# Espressif register map
File version: 1.0
CPU: Xtensa LX6 1, little endian, no MPU, FPU, 3 interrupt priority bits
Registers are 32-bit, access not given, reset 0x0 unless marked. A register's access mark holds for its fields unless they carry their own. Offsets are from the block's base; [hi:lo] are bit positions; {n}, {i} and the like mark numbered series.

## PWM0
Base 0x00000000
Same registers: PWM1 0x3FF6C000, PWM2 0x3FF6F000, PWM3 0x3FF70000
0x00 MCPWM_CLK_CFG
  [7:0] MCPWM_CLK_PRESCALE
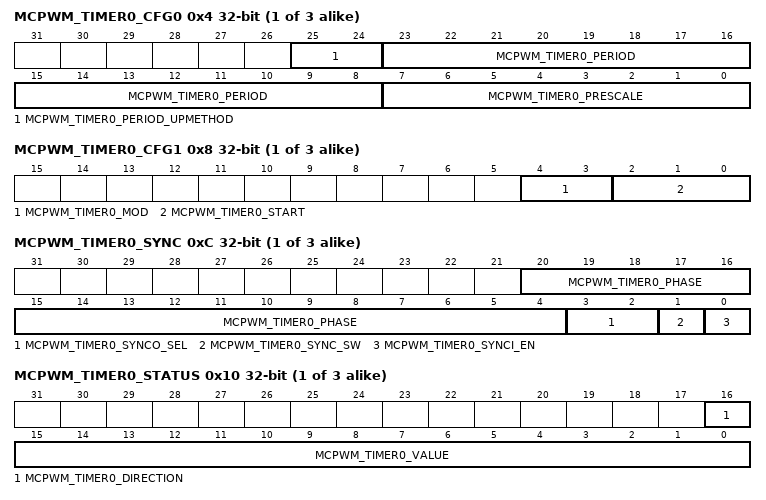
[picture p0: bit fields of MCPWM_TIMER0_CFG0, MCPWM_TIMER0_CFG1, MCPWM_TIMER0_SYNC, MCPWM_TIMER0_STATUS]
{0x4+0x10*i} MCPWM_TIMER{i}_CFG0 (i=0..2)
  [25:24] MCPWM_TIMER{i}_PERIOD_UPMETHOD, [23:8] MCPWM_TIMER{i}_PERIOD, [7:0] MCPWM_TIMER{i}_PRESCALE
{0x8+0x10*i} MCPWM_TIMER{i}_CFG1 (i=0..2)
  [4:3] MCPWM_TIMER{i}_MOD, [2:0] MCPWM_TIMER{i}_START
{0xC+0x10*i} MCPWM_TIMER{i}_SYNC (i=0..2)
  [20:4] MCPWM_TIMER{i}_PHASE, [3:2] MCPWM_TIMER{i}_SYNCO_SEL, [1] MCPWM_TIMER{i}_SYNC_SW, [0] MCPWM_TIMER{i}_SYNCI_EN
{0x10+0x10*i} MCPWM_TIMER{i}_STATUS (i=0..2)
  [16] MCPWM_TIMER{i}_DIRECTION, [15:0] MCPWM_TIMER{i}_VALUE
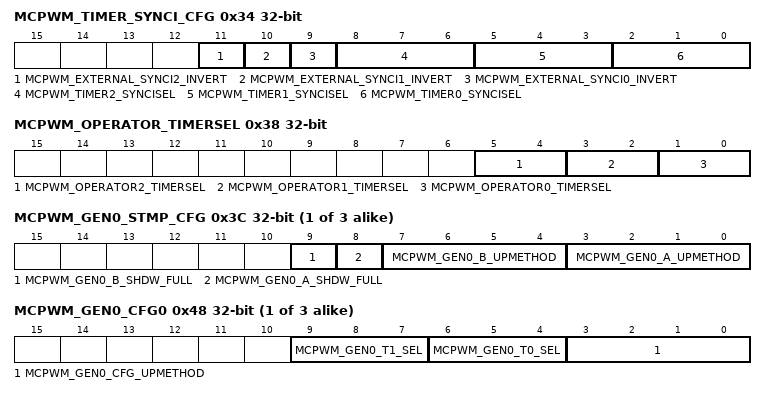
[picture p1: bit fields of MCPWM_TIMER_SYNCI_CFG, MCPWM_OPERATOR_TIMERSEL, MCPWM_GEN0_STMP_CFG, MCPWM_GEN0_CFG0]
0x34 MCPWM_TIMER_SYNCI_CFG
  [11] MCPWM_EXTERNAL_SYNCI2_INVERT, [10] MCPWM_EXTERNAL_SYNCI1_INVERT, [9] MCPWM_EXTERNAL_SYNCI0_INVERT, [8:6] MCPWM_TIMER2_SYNCISEL, [5:3] MCPWM_TIMER1_SYNCISEL, [2:0] MCPWM_TIMER0_SYNCISEL
0x38 MCPWM_OPERATOR_TIMERSEL
  [5:4] MCPWM_OPERATOR2_TIMERSEL, [3:2] MCPWM_OPERATOR1_TIMERSEL, [1:0] MCPWM_OPERATOR0_TIMERSEL
{0x3C+0x38*i} MCPWM_GEN{i}_STMP_CFG (i=0..2)
  [9] MCPWM_GEN{i}_B_SHDW_FULL, [8] MCPWM_GEN{i}_A_SHDW_FULL, [7:4] MCPWM_GEN{i}_B_UPMETHOD, [3:0] MCPWM_GEN{i}_A_UPMETHOD
{0x40+0x38*i} MCPWM_GEN{i}_TSTMP_A (i=0..2)
  [15:0] MCPWM_GEN{i}_A
{0x44+0x38*i} MCPWM_GEN{i}_TSTMP_B (i=0..2)
  [15:0] MCPWM_GEN{i}_B
{0x48+0x38*i} MCPWM_GEN{i}_CFG0 (i=0..2)
  [9:7] MCPWM_GEN{i}_T1_SEL, [6:4] MCPWM_GEN{i}_T0_SEL, [3:0] MCPWM_GEN{i}_CFG_UPMETHOD
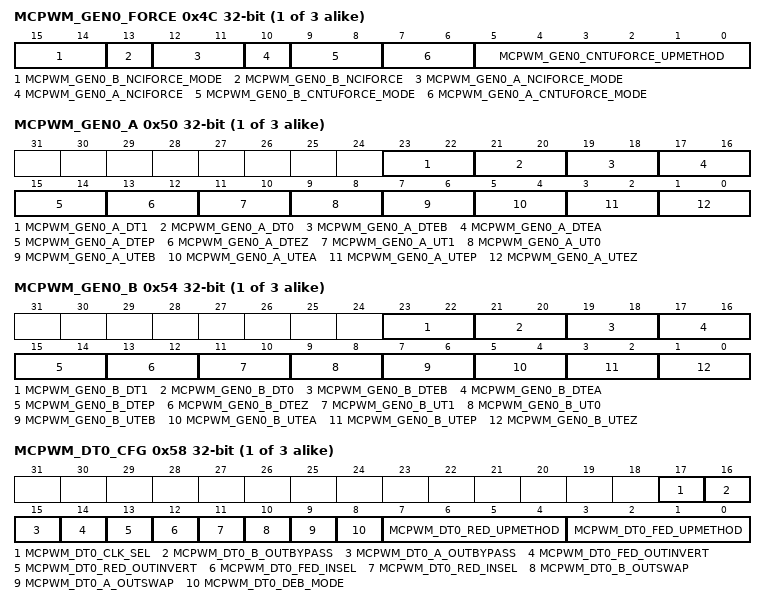
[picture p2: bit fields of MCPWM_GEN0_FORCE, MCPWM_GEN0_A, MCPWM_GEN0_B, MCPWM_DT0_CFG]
{0x4C+0x38*i} MCPWM_GEN{i}_FORCE (i=0..2)
  [15:14] MCPWM_GEN{i}_B_NCIFORCE_MODE, [13] MCPWM_GEN{i}_B_NCIFORCE, [12:11] MCPWM_GEN{i}_A_NCIFORCE_MODE, [10] MCPWM_GEN{i}_A_NCIFORCE, [9:8] MCPWM_GEN{i}_B_CNTUFORCE_MODE, [7:6] MCPWM_GEN{i}_A_CNTUFORCE_MODE, [5:0] MCPWM_GEN{i}_CNTUFORCE_UPMETHOD
{0x50+0x38*i} MCPWM_GEN{i}_A (i=0..2)
  [23:22] MCPWM_GEN{i}_A_DT1, [21:20] MCPWM_GEN{i}_A_DT0, [19:18] MCPWM_GEN{i}_A_DTEB, [17:16] MCPWM_GEN{i}_A_DTEA, [15:14] MCPWM_GEN{i}_A_DTEP, [13:12] MCPWM_GEN{i}_A_DTEZ, [11:10] MCPWM_GEN{i}_A_UT1, [9:8] MCPWM_GEN{i}_A_UT0, [7:6] MCPWM_GEN{i}_A_UTEB, [5:4] MCPWM_GEN{i}_A_UTEA, [3:2] MCPWM_GEN{i}_A_UTEP, [1:0] MCPWM_GEN{i}_A_UTEZ
{0x54+0x38*i} MCPWM_GEN{i}_B (i=0..2)
  [23:22] MCPWM_GEN{i}_B_DT1, [21:20] MCPWM_GEN{i}_B_DT0, [19:18] MCPWM_GEN{i}_B_DTEB, [17:16] MCPWM_GEN{i}_B_DTEA, [15:14] MCPWM_GEN{i}_B_DTEP, [13:12] MCPWM_GEN{i}_B_DTEZ, [11:10] MCPWM_GEN{i}_B_UT1, [9:8] MCPWM_GEN{i}_B_UT0, [7:6] MCPWM_GEN{i}_B_UTEB, [5:4] MCPWM_GEN{i}_B_UTEA, [3:2] MCPWM_GEN{i}_B_UTEP, [1:0] MCPWM_GEN{i}_B_UTEZ
{0x58+0x38*i} MCPWM_DT{i}_CFG (i=0..2)
  [17] MCPWM_DT{i}_CLK_SEL, [16] MCPWM_DT{i}_B_OUTBYPASS, [15] MCPWM_DT{i}_A_OUTBYPASS, [14] MCPWM_DT{i}_FED_OUTINVERT, [13] MCPWM_DT{i}_RED_OUTINVERT, [12] MCPWM_DT{i}_FED_INSEL, [11] MCPWM_DT{i}_RED_INSEL, [10] MCPWM_DT{i}_B_OUTSWAP, [9] MCPWM_DT{i}_A_OUTSWAP, [8] MCPWM_DT{i}_DEB_MODE, [7:4] MCPWM_DT{i}_RED_UPMETHOD, [3:0] MCPWM_DT{i}_FED_UPMETHOD
{0x5C+0x38*i} MCPWM_DT{i}_FED_CFG (i=0..2)
  [15:0] MCPWM_DT{i}_FED
{0x60+0x38*i} MCPWM_DT{i}_RED_CFG (i=0..2)
  [15:0] MCPWM_DT{i}_RED
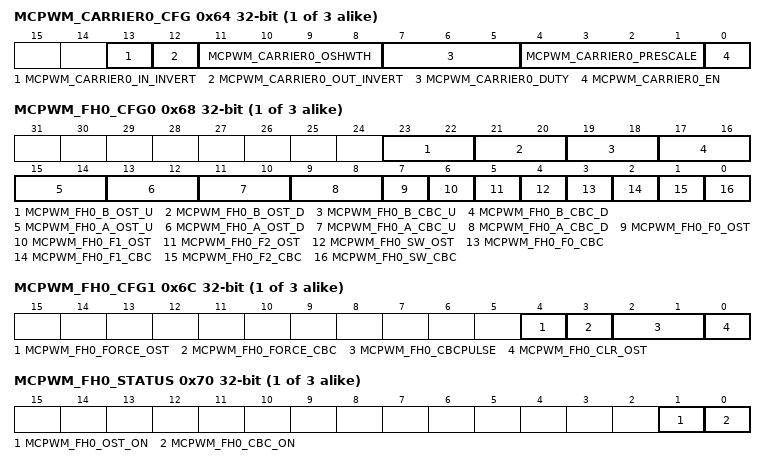
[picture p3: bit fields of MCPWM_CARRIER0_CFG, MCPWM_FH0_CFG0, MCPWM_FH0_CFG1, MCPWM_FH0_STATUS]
{0x64+0x38*i} MCPWM_CARRIER{i}_CFG (i=0..2)
  [13] MCPWM_CARRIER{i}_IN_INVERT, [12] MCPWM_CARRIER{i}_OUT_INVERT, [11:8] MCPWM_CARRIER{i}_OSHWTH, [7:5] MCPWM_CARRIER{i}_DUTY, [4:1] MCPWM_CARRIER{i}_PRESCALE, [0] MCPWM_CARRIER{i}_EN
{0x68+0x38*i} MCPWM_FH{i}_CFG0 (i=0..2)
  [23:22] MCPWM_FH{i}_B_OST_U, [21:20] MCPWM_FH{i}_B_OST_D, [19:18] MCPWM_FH{i}_B_CBC_U, [17:16] MCPWM_FH{i}_B_CBC_D, [15:14] MCPWM_FH{i}_A_OST_U, [13:12] MCPWM_FH{i}_A_OST_D, [11:10] MCPWM_FH{i}_A_CBC_U, [9:8] MCPWM_FH{i}_A_CBC_D, [7] MCPWM_FH{i}_F0_OST, [6] MCPWM_FH{i}_F1_OST, [5] MCPWM_FH{i}_F2_OST, [4] MCPWM_FH{i}_SW_OST, [3] MCPWM_FH{i}_F0_CBC, [2] MCPWM_FH{i}_F1_CBC, [1] MCPWM_FH{i}_F2_CBC, [0] MCPWM_FH{i}_SW_CBC
{0x6C+0x38*i} MCPWM_FH{i}_CFG1 (i=0..2)
  [4] MCPWM_FH{i}_FORCE_OST, [3] MCPWM_FH{i}_FORCE_CBC, [2:1] MCPWM_FH{i}_CBCPULSE, [0] MCPWM_FH{i}_CLR_OST
{0x70+0x38*i} MCPWM_FH{i}_STATUS (i=0..2)
  [1] MCPWM_FH{i}_OST_ON, [0] MCPWM_FH{i}_CBC_ON
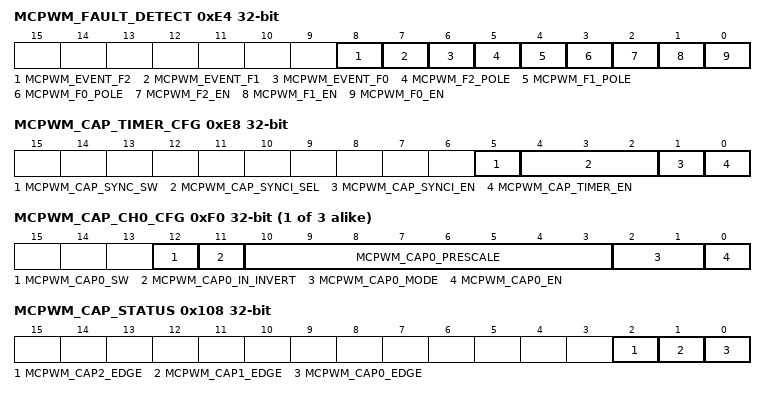
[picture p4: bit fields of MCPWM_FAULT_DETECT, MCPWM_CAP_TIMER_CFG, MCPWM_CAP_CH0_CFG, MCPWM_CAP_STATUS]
0xE4 MCPWM_FAULT_DETECT
  [8] MCPWM_EVENT_F2, [7] MCPWM_EVENT_F1, [6] MCPWM_EVENT_F0, [5] MCPWM_F2_POLE, [4] MCPWM_F1_POLE, [3] MCPWM_F0_POLE, [2] MCPWM_F2_EN, [1] MCPWM_F1_EN, [0] MCPWM_F0_EN
0xE8 MCPWM_CAP_TIMER_CFG
  [5] MCPWM_CAP_SYNC_SW, [4:2] MCPWM_CAP_SYNCI_SEL, [1] MCPWM_CAP_SYNCI_EN, [0] MCPWM_CAP_TIMER_EN
0xEC MCPWM_CAP_TIMER_PHASE
  [31:0] MCPWM_CAP_PHASE
{0xF0+4i} MCPWM_CAP_CH{i}_CFG (i=0..2)
  [12] MCPWM_CAP{i}_SW, [11] MCPWM_CAP{i}_IN_INVERT, [10:3] MCPWM_CAP{i}_PRESCALE, [2:1] MCPWM_CAP{i}_MODE, [0] MCPWM_CAP{i}_EN
{0xFC+4i} MCPWM_CAP_CH{i} (i=0..2)
  [31:0] MCPWM_CAP{i}_VALUE
0x108 MCPWM_CAP_STATUS
  [2] MCPWM_CAP2_EDGE, [1] MCPWM_CAP1_EDGE, [0] MCPWM_CAP0_EDGE
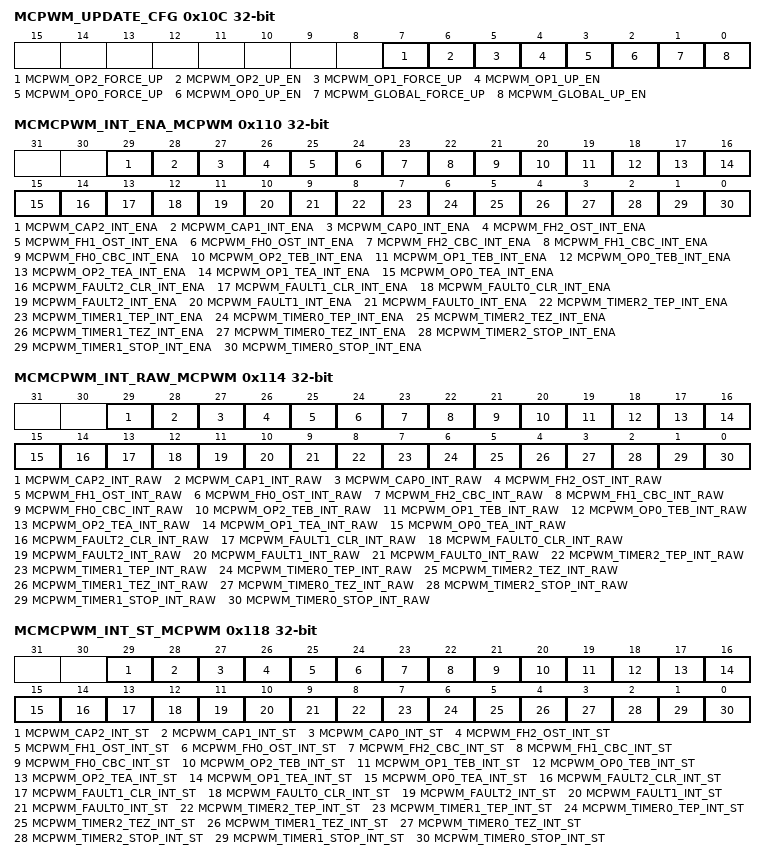
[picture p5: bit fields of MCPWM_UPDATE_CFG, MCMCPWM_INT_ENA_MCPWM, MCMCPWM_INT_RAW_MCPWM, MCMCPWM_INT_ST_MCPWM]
0x10C MCPWM_UPDATE_CFG
  [7] MCPWM_OP2_FORCE_UP, [6] MCPWM_OP2_UP_EN, [5] MCPWM_OP1_FORCE_UP, [4] MCPWM_OP1_UP_EN, [3] MCPWM_OP0_FORCE_UP, [2] MCPWM_OP0_UP_EN, [1] MCPWM_GLOBAL_FORCE_UP, [0] MCPWM_GLOBAL_UP_EN
0x110 MCMCPWM_INT_ENA_MCPWM
  [29] MCPWM_CAP2_INT_ENA, [28] MCPWM_CAP1_INT_ENA, [27] MCPWM_CAP0_INT_ENA, [26] MCPWM_FH2_OST_INT_ENA, [25] MCPWM_FH1_OST_INT_ENA, [24] MCPWM_FH0_OST_INT_ENA, [23] MCPWM_FH2_CBC_INT_ENA, [22] MCPWM_FH1_CBC_INT_ENA, [21] MCPWM_FH0_CBC_INT_ENA, [20] MCPWM_OP2_TEB_INT_ENA, [19] MCPWM_OP1_TEB_INT_ENA, [18] MCPWM_OP0_TEB_INT_ENA, [17] MCPWM_OP2_TEA_INT_ENA, [16] MCPWM_OP1_TEA_INT_ENA, [15] MCPWM_OP0_TEA_INT_ENA, [14] MCPWM_FAULT2_CLR_INT_ENA, [13] MCPWM_FAULT1_CLR_INT_ENA, [12] MCPWM_FAULT0_CLR_INT_ENA, [11] MCPWM_FAULT2_INT_ENA, [10] MCPWM_FAULT1_INT_ENA, [9] MCPWM_FAULT0_INT_ENA, [8] MCPWM_TIMER2_TEP_INT_ENA, [7] MCPWM_TIMER1_TEP_INT_ENA, [6] MCPWM_TIMER0_TEP_INT_ENA, [5] MCPWM_TIMER2_TEZ_INT_ENA, [4] MCPWM_TIMER1_TEZ_INT_ENA, [3] MCPWM_TIMER0_TEZ_INT_ENA, [2] MCPWM_TIMER2_STOP_INT_ENA, [1] MCPWM_TIMER1_STOP_INT_ENA, [0] MCPWM_TIMER0_STOP_INT_ENA
0x114 MCMCPWM_INT_RAW_MCPWM
  [29] MCPWM_CAP2_INT_RAW, [28] MCPWM_CAP1_INT_RAW, [27] MCPWM_CAP0_INT_RAW, [26] MCPWM_FH2_OST_INT_RAW, [25] MCPWM_FH1_OST_INT_RAW, [24] MCPWM_FH0_OST_INT_RAW, [23] MCPWM_FH2_CBC_INT_RAW, [22] MCPWM_FH1_CBC_INT_RAW, [21] MCPWM_FH0_CBC_INT_RAW, [20] MCPWM_OP2_TEB_INT_RAW, [19] MCPWM_OP1_TEB_INT_RAW, [18] MCPWM_OP0_TEB_INT_RAW, [17] MCPWM_OP2_TEA_INT_RAW, [16] MCPWM_OP1_TEA_INT_RAW, [15] MCPWM_OP0_TEA_INT_RAW, [14] MCPWM_FAULT2_CLR_INT_RAW, [13] MCPWM_FAULT1_CLR_INT_RAW, [12] MCPWM_FAULT0_CLR_INT_RAW, [11] MCPWM_FAULT2_INT_RAW, [10] MCPWM_FAULT1_INT_RAW, [9] MCPWM_FAULT0_INT_RAW, [8] MCPWM_TIMER2_TEP_INT_RAW, [7] MCPWM_TIMER1_TEP_INT_RAW, [6] MCPWM_TIMER0_TEP_INT_RAW, [5] MCPWM_TIMER2_TEZ_INT_RAW, [4] MCPWM_TIMER1_TEZ_INT_RAW, [3] MCPWM_TIMER0_TEZ_INT_RAW, [2] MCPWM_TIMER2_STOP_INT_RAW, [1] MCPWM_TIMER1_STOP_INT_RAW, [0] MCPWM_TIMER0_STOP_INT_RAW
0x118 MCMCPWM_INT_ST_MCPWM
  [29] MCPWM_CAP2_INT_ST, [28] MCPWM_CAP1_INT_ST, [27] MCPWM_CAP0_INT_ST, [26] MCPWM_FH2_OST_INT_ST, [25] MCPWM_FH1_OST_INT_ST, [24] MCPWM_FH0_OST_INT_ST, [23] MCPWM_FH2_CBC_INT_ST, [22] MCPWM_FH1_CBC_INT_ST, [21] MCPWM_FH0_CBC_INT_ST, [20] MCPWM_OP2_TEB_INT_ST, [19] MCPWM_OP1_TEB_INT_ST, [18] MCPWM_OP0_TEB_INT_ST, [17] MCPWM_OP2_TEA_INT_ST, [16] MCPWM_OP1_TEA_INT_ST, [15] MCPWM_OP0_TEA_INT_ST, [14] MCPWM_FAULT2_CLR_INT_ST, [13] MCPWM_FAULT1_CLR_INT_ST, [12] MCPWM_FAULT0_CLR_INT_ST, [11] MCPWM_FAULT2_INT_ST, [10] MCPWM_FAULT1_INT_ST, [9] MCPWM_FAULT0_INT_ST, [8] MCPWM_TIMER2_TEP_INT_ST, [7] MCPWM_TIMER1_TEP_INT_ST, [6] MCPWM_TIMER0_TEP_INT_ST, [5] MCPWM_TIMER2_TEZ_INT_ST, [4] MCPWM_TIMER1_TEZ_INT_ST, [3] MCPWM_TIMER0_TEZ_INT_ST, [2] MCPWM_TIMER2_STOP_INT_ST, [1] MCPWM_TIMER1_STOP_INT_ST, [0] MCPWM_TIMER0_STOP_INT_ST
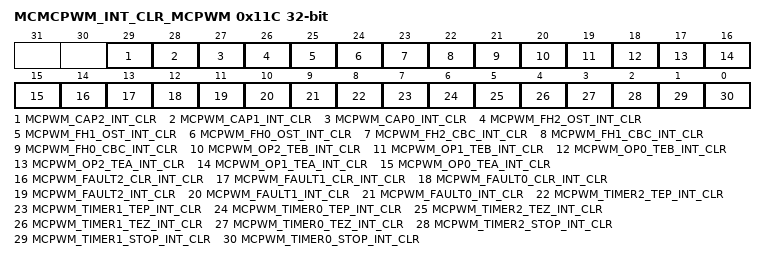
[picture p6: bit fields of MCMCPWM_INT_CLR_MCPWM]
0x11C MCMCPWM_INT_CLR_MCPWM
  [29] MCPWM_CAP2_INT_CLR, [28] MCPWM_CAP1_INT_CLR, [27] MCPWM_CAP0_INT_CLR, [26] MCPWM_FH2_OST_INT_CLR, [25] MCPWM_FH1_OST_INT_CLR, [24] MCPWM_FH0_OST_INT_CLR, [23] MCPWM_FH2_CBC_INT_CLR, [22] MCPWM_FH1_CBC_INT_CLR, [21] MCPWM_FH0_CBC_INT_CLR, [20] MCPWM_OP2_TEB_INT_CLR, [19] MCPWM_OP1_TEB_INT_CLR, [18] MCPWM_OP0_TEB_INT_CLR, [17] MCPWM_OP2_TEA_INT_CLR, [16] MCPWM_OP1_TEA_INT_CLR, [15] MCPWM_OP0_TEA_INT_CLR, [14] MCPWM_FAULT2_CLR_INT_CLR, [13] MCPWM_FAULT1_CLR_INT_CLR, [12] MCPWM_FAULT0_CLR_INT_CLR, [11] MCPWM_FAULT2_INT_CLR, [10] MCPWM_FAULT1_INT_CLR, [9] MCPWM_FAULT0_INT_CLR, [8] MCPWM_TIMER2_TEP_INT_CLR, [7] MCPWM_TIMER1_TEP_INT_CLR, [6] MCPWM_TIMER0_TEP_INT_CLR, [5] MCPWM_TIMER2_TEZ_INT_CLR, [4] MCPWM_TIMER1_TEZ_INT_CLR, [3] MCPWM_TIMER0_TEZ_INT_CLR, [2] MCPWM_TIMER2_STOP_INT_CLR, [1] MCPWM_TIMER1_STOP_INT_CLR, [0] MCPWM_TIMER0_STOP_INT_CLR
0x120 MCPWM_CLK
  [0] MCPWM_CLK_EN
0x124 MCPWM_VERSION
  [27:0] MCPWM_DATE
